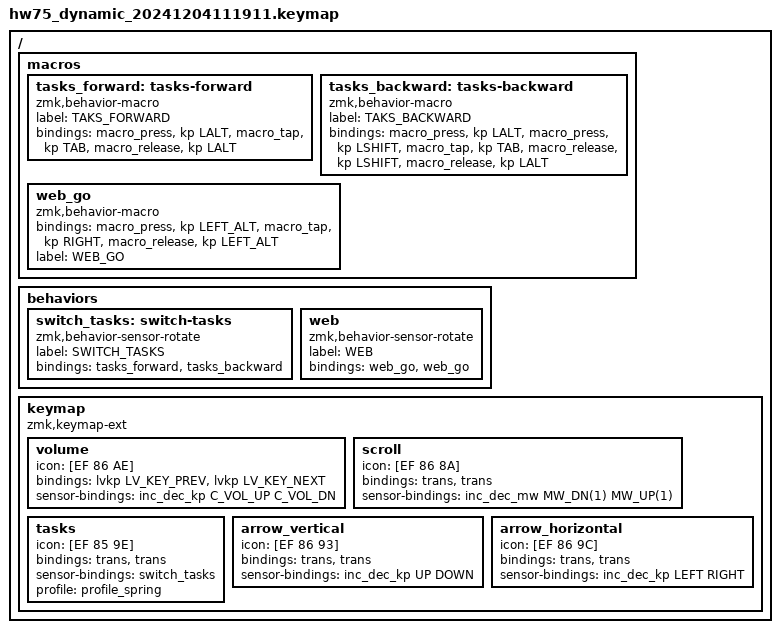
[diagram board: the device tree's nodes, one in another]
/*
 * Copyright (c) 2022 The ZMK Contributors
 * SPDX-License-Identifier: MIT
 */

#include <behaviors/lvgl_key_press.dtsi>
#include <behaviors/sensor_rotate_mouse_wheel.dtsi>
#include <dt-bindings/zmk/lvgl.h>
#include <behaviors.dtsi>
#include <dt-bindings/zmk/keys.h>

/ {
    macros {
        tasks_forward: tasks-forward {
            label = "TAKS_FORWARD";
            compatible = "zmk,behavior-macro";
            #binding-cells = <0>;
            bindings =
                <&macro_press>,
                <&kp LALT>,
                <&macro_tap>,
                <&kp TAB>,
                <&macro_release>,
                <&kp LALT>;
        };

        tasks_backward: tasks-backward {
            label = "TAKS_BACKWARD";
            compatible = "zmk,behavior-macro";
            #binding-cells = <0>;
            bindings =
                <&macro_press>,
                <&kp LALT>,
                <&macro_press>,
                <&kp LSHIFT>,
                <&macro_tap>,
                <&kp TAB>,
                <&macro_release>,
                <&kp LSHIFT>,
                <&macro_release>,
                <&kp LALT>;
        };

        web_go: web_go {
            compatible = "zmk,behavior-macro";
            #binding-cells = <0>;
            bindings =
                <&macro_press>,
                <&kp LEFT_ALT>,
                <&macro_tap>,
                <&kp RIGHT>,
                <&macro_release>,
                <&kp LEFT_ALT>;

            label = "WEB_GO";
        };
    };

    behaviors {
        switch_tasks: switch-tasks {
            compatible = "zmk,behavior-sensor-rotate";
            label = "SWITCH_TASKS";
            #sensor-binding-cells = <0>;
            bindings = <&tasks_forward>, <&tasks_backward>;
        };

        web: web {
            compatible = "zmk,behavior-sensor-rotate";
            label = "WEB";
            #sensor-binding-cells = <0>;
            bindings = <&web_go>, <&web_go>;
        };
    };

    keymap {
        compatible = "zmk,keymap-ext", "zmk,keymap";

        volume {
            label = "音量";
            icon = [EF 86 AE];
            bindings = <&lvkp LV_KEY_PREV &lvkp LV_KEY_NEXT>;
            sensor-bindings = <&inc_dec_kp C_VOL_UP C_VOL_DN>;
        };

        scroll {
            label = "滚动";
            icon = [EF 86 8A];
            bindings = <&trans &trans>;
            sensor-bindings = <&inc_dec_mw MW_DN(1) MW_UP(1)>;
        };

        tasks {
            label = "窗口";
            icon = [EF 85 9E];
            bindings = <&trans &trans>;
            sensor-bindings = <&switch_tasks>;
            profile = <&profile_spring>;
        };

        arrow_vertical {
            label = "上下";
            icon = [EF 86 93];
            bindings = <&trans &trans>;
            sensor-bindings = <&inc_dec_kp UP DOWN>;
        };

        arrow_horizontal {
            label = "左右";
            icon = [EF 86 9C];
            bindings = <&trans &trans>;
            sensor-bindings = <&inc_dec_kp LEFT RIGHT>;
        };
    };
};
